# STM32F072x register map
Vendor: STM>; File version: 1.0
Registers are 32-bit, read-write, reset 0x0 unless marked. A register's access mark holds for its fields unless they carry their own. Offsets are from the block's base; [hi:lo] are bit positions; lines under a group give offsets from that group; {n}, {i} and the like mark numbered series.

## TSC — Touch sensing controller
Base 0x40024000
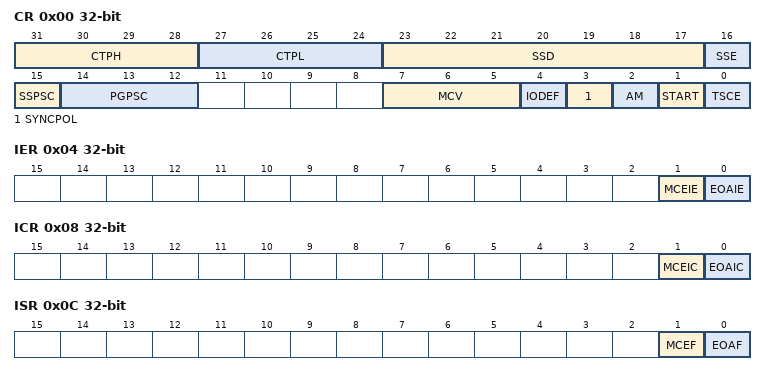
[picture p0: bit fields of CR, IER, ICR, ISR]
0x00 CR — control register
  [31:28] CTPH — Charge transfer pulse high
  [27:24] CTPL — Charge transfer pulse low
  [23:17] SSD — Spread spectrum deviation
  [16] SSE — Spread spectrum enable
  [15] SSPSC — Spread spectrum prescaler
  [14:12] PGPSC — pulse generator prescaler
  [7:5] MCV — Max count value
  [4] IODEF — I/O Default mode
  [3] SYNCPOL — Synchronization pin polarity
  [2] AM — Acquisition mode
  [1] START — Start a new acquisition
  [0] TSCE — Touch sensing controller enable
0x04 IER — interrupt enable register
  [1] MCEIE — Max count error interrupt enable
  [0] EOAIE — End of acquisition interrupt enable
0x08 ICR — interrupt clear register
  [1] MCEIC — Max count error interrupt clear
  [0] EOAIC — End of acquisition interrupt clear
0x0C ISR — interrupt status register
  [1] MCEF — Max count error flag
  [0] EOAF — End of acquisition flag
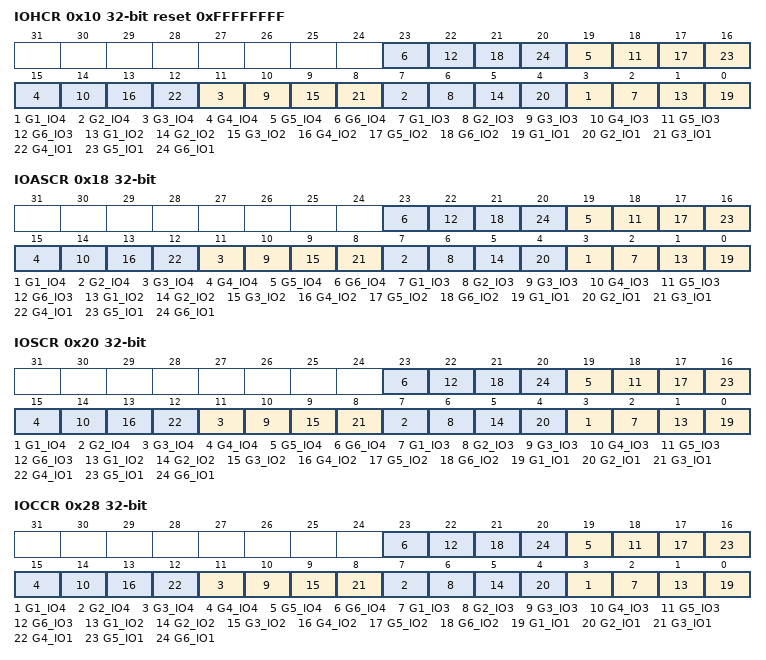
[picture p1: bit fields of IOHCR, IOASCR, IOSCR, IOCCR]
0x10 IOHCR reset 0xFFFFFFFF — I/O hysteresis control register
  [4n-1] G{n}_IO4 (n=1..6) — G{n}_IO4 Schmitt trigger hysteresis mode
  [4n-2] G{n}_IO3 (n=1..6) — G{n}_IO3 Schmitt trigger hysteresis mode
  [4n-3] G{n}_IO2 (n=1..6) — G{n}_IO2 Schmitt trigger hysteresis mode
  [4n-4] G{n}_IO1 (n=1..6) — G{n}_IO1 Schmitt trigger hysteresis mode
0x18 IOASCR — I/O analog switch control register
  [4n-1] G{n}_IO4 (n=1..6) — G{n}_IO4 analog switch enable
  [4n-2] G{n}_IO3 (n=1..6) — G{n}_IO3 analog switch enable
  [4n-3] G{n}_IO2 (n=1..6) — G{n}_IO2 analog switch enable
  [4n-4] G{n}_IO1 (n=1..6) — G{n}_IO1 analog switch enable
0x20 IOSCR — I/O sampling control register
  [4n-1] G{n}_IO4 (n=1..6) — G{n}_IO4 sampling mode
  [4n-2] G{n}_IO3 (n=1..6) — G{n}_IO3 sampling mode
  [4n-3] G{n}_IO2 (n=1..6) — G{n}_IO2 sampling mode
  [4n-4] G{n}_IO1 (n=1..6) — G{n}_IO1 sampling mode
0x28 IOCCR — I/O channel control register
  [4n-1] G{n}_IO4 (n=1..6) — G{n}_IO4 channel mode
  [4n-2] G{n}_IO3 (n=1..6) — G{n}_IO3 channel mode
  [4n-3] G{n}_IO2 (n=1..6) — G{n}_IO2 channel mode
  [4n-4] G{n}_IO1 (n=1..6) — G{n}_IO1 channel mode
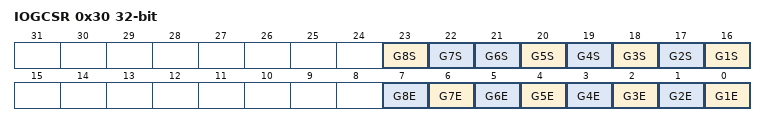
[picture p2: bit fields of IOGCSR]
0x30 IOGCSR access per field — I/O group control status register
  [23] G8S rw — Analog I/O group x status
  [22] G7S rw — Analog I/O group x status
  [n+15] G{n}S ro (n=1..6) — Analog I/O group x status
  [n-1] G{n}E rw (n=1..8) — Analog I/O group x enable
{0x30+4i} IOG{i}CR ro (i=1..6) — I/O group x counter register
  [13:0] CNT — Counter value

## CEC — HDMI-CEC controller
Base 0x40007800
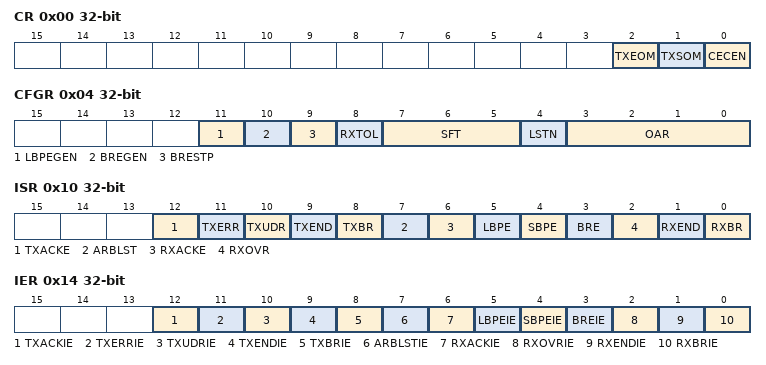
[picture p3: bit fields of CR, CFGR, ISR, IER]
0x00 CR — control register
  [2] TXEOM — Tx End Of Message
  [1] TXSOM — Tx start of message
  [0] CECEN — CEC Enable
0x04 CFGR — configuration register
  [11] LBPEGEN — Generate Error-Bit on Long Bit Period Error
  [10] BREGEN — Generate error-bit on bit rising error
  [9] BRESTP — Rx-stop on bit rising error
  [8] RXTOL — Rx-Tolerance
  [7:5] SFT — Signal Free Time
  [4] LSTN — Listen mode
  [3:0] OAR — Own Address
0x08 TXDR wo — Tx data register
  [7:0] TXD — Tx Data register
0x0C RXDR ro — Rx Data Register
  [7:0] RXDR — CEC Rx Data Register
0x10 ISR — Interrupt and Status Register
  [12] TXACKE — Tx-Missing acknowledge error
  [11] TXERR — Tx-Error
  [10] TXUDR — Tx-Buffer Underrun
  [9] TXEND — End of Transmission
  [8] TXBR — Tx-Byte Request
  [7] ARBLST — Arbitration Lost
  [6] RXACKE — Rx-Missing Acknowledge
  [5] LBPE — Rx-Long Bit Period Error
  [4] SBPE — Rx-Short Bit period error
  [3] BRE — Rx-Bit rising error
  [2] RXOVR — Rx-Overrun
  [1] RXEND — End Of Reception
  [0] RXBR — Rx-Byte Received
0x14 IER — interrupt enable register
  [12] TXACKIE — Tx-Missing Acknowledge Error Interrupt Enable
  [11] TXERRIE — Tx-Error Interrupt Enable
  [10] TXUDRIE — Tx-Underrun interrupt enable
  [9] TXENDIE — Tx-End of message interrupt enable
  [8] TXBRIE — Tx-Byte Request Interrupt Enable
  [7] ARBLSTIE — Arbitration Lost Interrupt Enable
  [6] RXACKIE — Rx-Missing Acknowledge Error Interrupt Enable
  [5] LBPEIE — Long Bit Period Error Interrupt Enable
  [4] SBPEIE — Short Bit Period Error Interrupt Enable
  [3] BREIE — Bit Rising Error Interrupt Enable
  [2] RXOVRIE — Rx-Buffer Overrun Interrupt Enable
  [1] RXENDIE — End Of Reception Interrupt Enable
  [0] RXBRIE — Rx-Byte Received Interrupt Enable
